# RA6M1 register map
Vendor: Renesas Electronics Corporation; Series: RA6; File version: 1.2
CPU: CM4 r0p1, little endian, MPU, FPU, VTOR, 4 interrupt priority bits
Registers are 8-bit, read-write, reset 0x0 unless marked. A register's access mark holds for its fields unless they carry their own. Offsets are from the block's base; [hi:lo] are bit positions; {n}, {i} and the like mark numbered series; 'fields as' and 'values as' point back to an identical list.

## PFS — Pmn Pin Function Control Register
Base 0x40040800
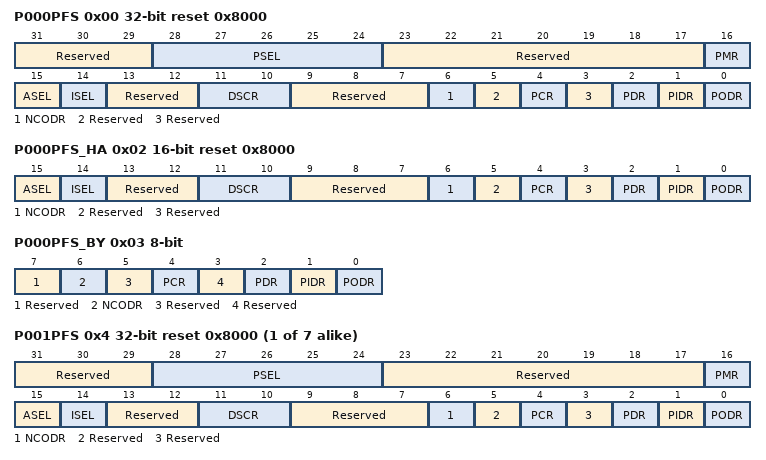
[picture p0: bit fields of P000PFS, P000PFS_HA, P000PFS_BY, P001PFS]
0x00 P000PFS 32-bit reset 0x8000 (reset mask 0xFFFFFFFD) — P000 Pin Function Control Register
  [31:29] Reserved — These bits are read as 000. The write value should be 000.
  [28:24] PSEL — Port Function Select These bits select the peripheral function. For individual pin functions, see the MPC table
  [23:17] Reserved — These bits are read as 0000000. The write value should be 0000000.
  [16] PMR — Port Mode Control
    0=Uses the pin as a general I/O pin; 1=Uses the pin as an I/O port for peripheral functions
  [15] ASEL — Analog Input enable
    0=Used other than as analog pin; 1=Used as analog pin
  [14] ISEL — IRQ input enable
    0=Not used as IRQn input pin; 1=Used as IRQn input pin
  [13:12] Reserved — These bits are read as 00. The write value should be 00.
  [11:10] DSCR — Drive Strength Control Register
    0=Normal drive output; 1=Middle drive output; 2=Setting prohibited; 3=High-drive output
  [9:7] Reserved — These bits are read as 000. The write value should be 000.
  [6] NCODR — N-Channel Open Drain Control
    0=CMOS output; 1=NMOS open-drain output
  [5] Reserved — This bit is read as 0. The write value should be 0.
  [4] PCR — Pull-up Control
    0=Disables an input pull-up; 1=Enables an input pull-up
  [3] Reserved — This bit is read as 0. The write value should be 0.
  [2] PDR — Port Direction
    0=Input (Functions as an input pin.); 1=Output (Functions as an output pin.)
  [1] PIDR ro — Port Input Data
    0=Low input; 1=High input
  [0] PODR — Port Output Data
    0=Low output; 1=High output
0x02 P000PFS_HA 16-bit reset 0x8000 (reset mask 0xFFFD) (alternate view of P000PFS) — P000 Pin Function Control Register
  [15] ASEL — Analog Input enable
    0=Used other than as analog pin; 1=Used as analog pin
  [14] ISEL — IRQ input enable
    0=Not used as IRQn input pin; 1=Used as IRQn input pin
  [13:12] Reserved — These bits are read as 00. The write value should be 00.
  [11:10] DSCR — Drive Strength Control Register
    values as P000PFS.DSCR
  [9:7] Reserved — These bits are read as 000. The write value should be 000.
  [6] NCODR — N-Channel Open Drain Control
    0=CMOS output; 1=NMOS open-drain output
  [5] Reserved — This bit is read as 0. The write value should be 0.
  [4] PCR — Pull-up Control
    0=Disables an input pull-up; 1=Enables an input pull-up
  [3] Reserved — This bit is read as 0. The write value should be 0.
  [2] PDR — Port Direction
    values as P000PFS.PDR
  [1] PIDR ro — Port Input Data
    0=Low input; 1=High input
  [0] PODR — Port Output Data
    0=Low output; 1=High output
0x03 P000PFS_BY (reset mask 0xFD) (alternate view of P000PFS) — P000 Pin Function Control Register
  [7] Reserved — This bit is read as 0. The write value should be 0.
  [6] NCODR — N-Channel Open Drain Control
    0=CMOS output; 1=NMOS open-drain output
  [5] Reserved — This bit is read as 0. The write value should be 0.
  [4] PCR — Pull-up Control
    0=Disables an input pull-up; 1=Enables an input pull-up
  [3] Reserved — This bit is read as 0. The write value should be 0.
  [2] PDR — Port Direction
    values as P000PFS.PDR
  [1] PIDR ro — Port Input Data
    0=Low input; 1=High input
  [0] PODR — Port Output Data
    0=Low output; 1=High output
{0x0+4i} P00{i}PFS (i=1..7) 32-bit reset 0x8000 (reset mask 0xFFFFFFFD) — P00{i} Pin Function Control Register
  fields as P000PFS
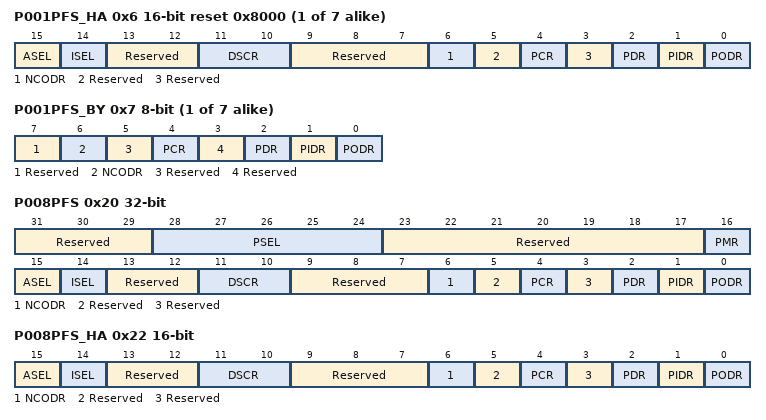
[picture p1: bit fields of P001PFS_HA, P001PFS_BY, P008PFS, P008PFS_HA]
{0x2+4i} P00{i}PFS_HA (i=1..7) 16-bit reset 0x8000 (reset mask 0xFFFD) (alternate view of P00{i}PFS) — P00{i} Pin Function Control Register
  fields as P000PFS_HA
{0x3+4i} P00{i}PFS_BY (i=1..7) (reset mask 0xFD) (alternate view of P00{i}PFS) — P00{i} Pin Function Control Register
  fields as P000PFS_BY
0x20 P008PFS 32-bit (reset mask 0xFFFFFFFD) — P008 Pin Function Control Register
  fields as P000PFS
0x22 P008PFS_HA 16-bit (reset mask 0xFFFD) (alternate view of P00*PFS) — P008 Pin Function Control Register
  fields as P000PFS_HA
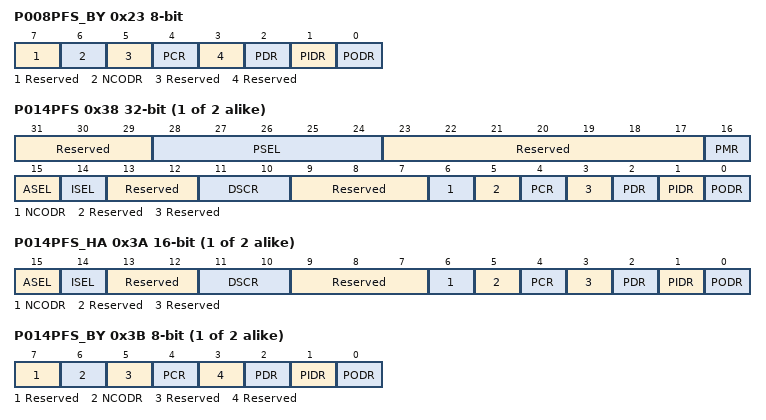
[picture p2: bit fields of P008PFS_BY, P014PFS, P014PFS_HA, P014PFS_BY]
0x23 P008PFS_BY (reset mask 0xFD) (alternate view of P00*PFS) — P008 Pin Function Control Register
  fields as P000PFS_BY
{0x0+4i} P0{i}PFS (i=14..15) 32-bit (reset mask 0xFFFFFFFD) — P0{i} Pin Function Control Register
  fields as P000PFS
{0x2+4i} P0{i}PFS_HA (i=14..15) 16-bit (reset mask 0xFFFD) — P0{i} Pin Function Control Register
  fields as P000PFS_HA
{0x3+4i} P0{i}PFS_BY (i=14..15) (reset mask 0xFD) — P0{i} Pin Function Control Register
  fields as P000PFS_BY
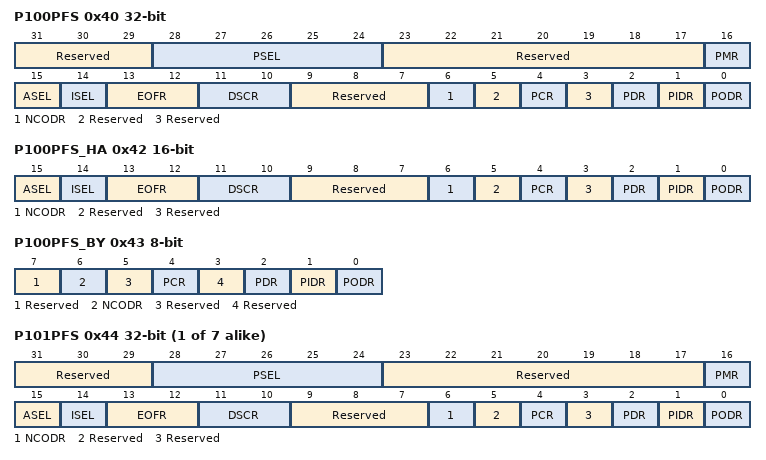
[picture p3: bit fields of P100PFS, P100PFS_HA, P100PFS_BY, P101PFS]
0x40 P100PFS 32-bit (reset mask 0xFFFFFFFD) — P100 Pin Function Control Register
  [31:29] Reserved — These bits are read as 000. The write value should be 000.
  [28:24] PSEL — Port Function Select These bits select the peripheral function. For individual pin functions, see the MPC table
  [23:17] Reserved — These bits are read as 0000000. The write value should be 0000000.
  [16] PMR — Port Mode Control
    values as P000PFS.PMR
  [15] ASEL — Analog Input enable
    0=Used other than as analog pin; 1=Used as analog pin
  [14] ISEL — IRQ input enable
    0=Not used as IRQn input pin; 1=Used as IRQn input pin
  [13:12] EOFR — Event on Falling/Event on Rising
    0=Don’t-care; 1=Detect rising edge; 2=Detect falling edge; 3=Detect both edges
  [11:10] DSCR — Drive Strength Control Register
    values as P000PFS.DSCR
  [9:7] Reserved — These bits are read as 000. The write value should be 000.
  [6] NCODR — N-Channel Open Drain Control
    0=CMOS output; 1=NMOS open-drain output
  [5] Reserved — This bit is read as 0. The write value should be 0.
  [4] PCR — Pull-up Control
    0=Disables an input pull-up; 1=Enables an input pull-up
  [3] Reserved — This bit is read as 0. The write value should be 0.
  [2] PDR — Port Direction
    values as P000PFS.PDR
  [1] PIDR ro — Port Input Data
    0=Low input; 1=High input
  [0] PODR — Port Output Data
    0=Low output; 1=High output
0x42 P100PFS_HA 16-bit (reset mask 0xFFFD) — P100 Pin Function Control Register
  [15] ASEL — Analog Input enable
    0=Used other than as analog pin; 1=Used as analog pin
  [14] ISEL — IRQ input enable
    0=Not used as IRQn input pin; 1=Used as IRQn input pin
  [13:12] EOFR — Event on Falling/Event on Rising
    values as P100PFS.EOFR
  [11:10] DSCR — Drive Strength Control Register
    values as P000PFS.DSCR
  [9:7] Reserved — These bits are read as 000. The write value should be 000.
  [6] NCODR — N-Channel Open Drain Control
    0=CMOS output; 1=NMOS open-drain output
  [5] Reserved — This bit is read as 0. The write value should be 0.
  [4] PCR — Pull-up Control
    0=Disables an input pull-up; 1=Enables an input pull-up
  [3] Reserved — This bit is read as 0. The write value should be 0.
  [2] PDR — Port Direction
    values as P000PFS.PDR
  [1] PIDR ro — Port Input Data
    0=Low input; 1=High input
  [0] PODR — Port Output Data
    0=Low output; 1=High output
0x43 P100PFS_BY (reset mask 0xFD) — P100 Pin Function Control Register
  fields as P000PFS_BY
{0x40+4i} P10{i}PFS (i=1..7) 32-bit (reset mask 0xFFFFFFFD) (alternate view of P10{i}PFS) — P10{i} Pin Function Control Register
  fields as P100PFS
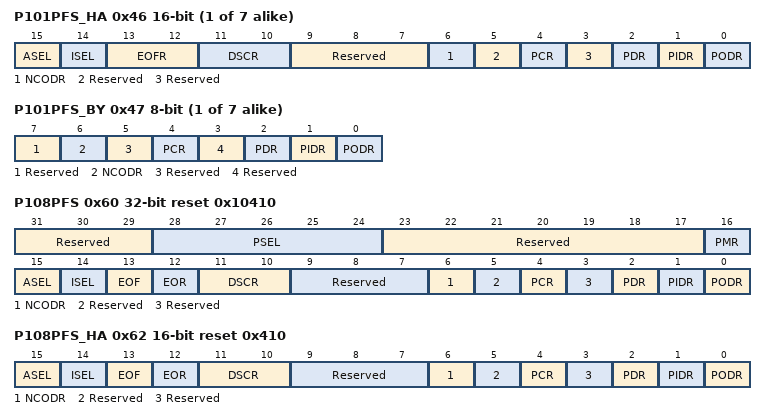
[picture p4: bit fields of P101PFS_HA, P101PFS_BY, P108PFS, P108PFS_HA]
{0x42+4i} P10{i}PFS_HA (i=1..7) 16-bit (reset mask 0xFFFD) (alternate view of P10{i}PFS) — P10{i} Pin Function Control Register
  fields as P100PFS_HA
{0x43+4i} P10{i}PFS_BY (i=1..7) (reset mask 0xFD) (alternate view of P10{i}PFS) — P10{i} Pin Function Control Register
  fields as P000PFS_BY
0x60 P108PFS 32-bit reset 0x10410 (reset mask 0xFFFFFFFD) — P108 Pin Function Control Register
  [31:29] Reserved — These bits are read as 000. The write value should be 000.
  [28:24] PSEL — Port Function Select These bits select the peripheral function. For individual pin functions, see the MPC table
  [23:17] Reserved — These bits are read as 0000000. The write value should be 0000000.
  [16] PMR — Port Mode Control
    values as P000PFS.PMR
  [15] ASEL — Analog Input enable
    0=Used other than as analog pin; 1=Used as analog pin
  [14] ISEL — IRQ input enable
    0=Not used as IRQn input pin; 1=Used as IRQn input pin
  [13] EOF — Event on Falling
    0=Do not care; 1=Detect falling edge
  [12] EOR — Event on Rising
    0=Do not care; 1=Detect rising edge
  [11:10] DSCR — Drive Strength Control Register
    values as P000PFS.DSCR
  [9:7] Reserved — These bits are read as 000. The write value should be 000.
  [6] NCODR — N-Channel Open Drain Control
    0=CMOS output; 1=NMOS open-drain output
  [5] Reserved — This bit is read as 0. The write value should be 0.
  [4] PCR — Pull-up Control
    0=Disables an input pull-up; 1=Enables an input pull-up
  [3] Reserved — This bit is read as 0. The write value should be 0.
  [2] PDR — Port Direction
    values as P000PFS.PDR
  [1] PIDR ro — Port Input Data
    0=Low input; 1=High input
  [0] PODR — Port Output Data
    0=Low output; 1=High output
0x62 P108PFS_HA 16-bit reset 0x410 (reset mask 0xFFFD) (alternate view of P108PFS) — P108 Pin Function Control Register
  [15] ASEL — Analog Input enable
    0=Used other than as analog pin; 1=Used as analog pin
  [14] ISEL — IRQ input enable
    0=Not used as IRQn input pin; 1=Used as IRQn input pin
  [13] EOF — Event on Falling
    0=Do not care; 1=Detect falling edge
  [12] EOR — Event on Rising
    0=Do not care; 1=Detect rising edge
  [11:10] DSCR — Drive Strength Control Register
    values as P000PFS.DSCR
  [9:7] Reserved — These bits are read as 000. The write value should be 000.
  [6] NCODR — N-Channel Open Drain Control
    0=CMOS output; 1=NMOS open-drain output
  [5] Reserved — This bit is read as 0. The write value should be 0.
  [4] PCR — Pull-up Control
    0=Disables an input pull-up; 1=Enables an input pull-up
  [3] Reserved — This bit is read as 0. The write value should be 0.
  [2] PDR — Port Direction
    values as P000PFS.PDR
  [1] PIDR ro — Port Input Data
    0=Low input; 1=High input
  [0] PODR — Port Output Data
    0=Low output; 1=High output
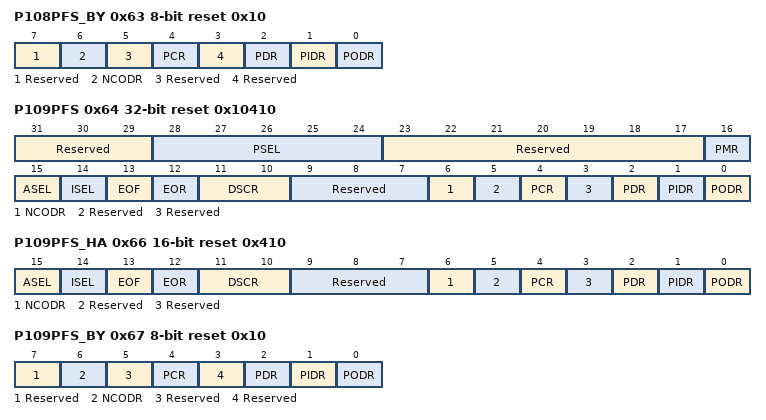
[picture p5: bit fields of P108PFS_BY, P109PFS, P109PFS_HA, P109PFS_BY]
0x63 P108PFS_BY reset 0x10 (reset mask 0xFD) (alternate view of P108PFS) — P108 Pin Function Control Register
  fields as P000PFS_BY
0x64 P109PFS 32-bit reset 0x10410 (reset mask 0xFFFFFFFD) — P109 Pin Function Control Register
  fields as P108PFS
0x66 P109PFS_HA 16-bit reset 0x410 (reset mask 0xFFFD) (alternate view of P109PFS) — P109 Pin Function Control Register
  fields as P108PFS_HA
0x67 P109PFS_BY reset 0x10 (reset mask 0xFD) (alternate view of P109PFS) — P109 Pin Function Control Register
  fields as P000PFS_BY
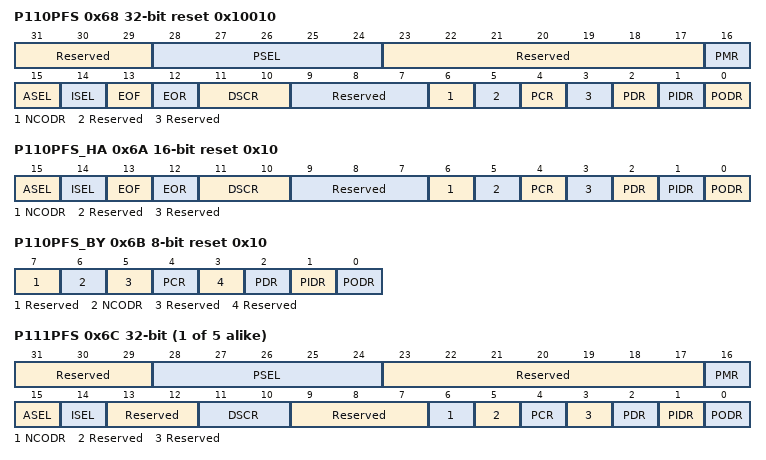
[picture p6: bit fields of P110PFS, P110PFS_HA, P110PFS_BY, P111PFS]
0x68 P110PFS 32-bit reset 0x10010 (reset mask 0xFFFFFFFD) — P110 Pin Function Control Register
  fields as P108PFS
0x6A P110PFS_HA 16-bit reset 0x10 (reset mask 0xFFFD) (alternate view of P110PFS) — P110 Pin Function Control Register
  fields as P108PFS_HA
0x6B P110PFS_BY reset 0x10 (reset mask 0xFD) (alternate view of P110PFS) — P110 Pin Function Control Register
  fields as P000PFS_BY
{0x40+4i} P1{i}PFS (i=11..15) 32-bit (reset mask 0xFFFFFFFD) — P1{i} Pin Function Control Register
  fields as P000PFS
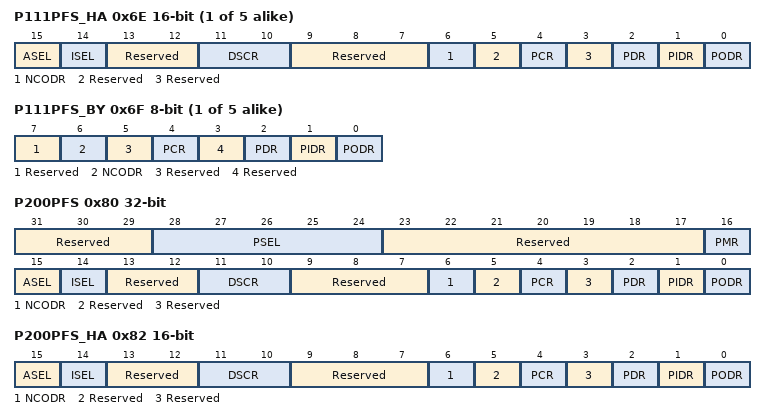
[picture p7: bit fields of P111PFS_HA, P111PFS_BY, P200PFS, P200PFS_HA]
{0x42+4i} P1{i}PFS_HA (i=11..15) 16-bit (reset mask 0xFFFD) (alternate view of P1{i}PFS) — P1{i} Pin Function Control Register
  fields as P000PFS_HA
{0x43+4i} P1{i}PFS_BY (i=11..15) (reset mask 0xFD) (alternate view of P1{i}PFS) — P1{i} Pin Function Control Register
  fields as P000PFS_BY
0x80 P200PFS 32-bit (reset mask 0xFFFFFFFD) — P200 Pin Function Control Register
  fields as P000PFS
0x82 P200PFS_HA 16-bit (reset mask 0xFFFD) (alternate view of P200PFS) — P200 Pin Function Control Register
  fields as P000PFS_HA
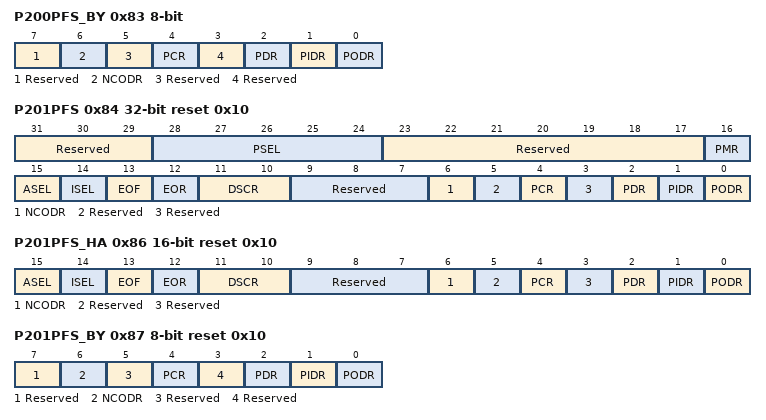
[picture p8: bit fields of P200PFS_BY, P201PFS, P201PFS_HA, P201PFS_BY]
0x83 P200PFS_BY (reset mask 0xFD) (alternate view of P200PFS) — P200 Pin Function Control Register
  fields as P000PFS_BY
0x84 P201PFS 32-bit reset 0x10 (reset mask 0xFFFFFFFD) — P201 Pin Function Control Register
  fields as P108PFS
0x86 P201PFS_HA 16-bit reset 0x10 (reset mask 0xFFFD) (alternate view of P201PFS) — P201 Pin Function Control Register
  fields as P108PFS_HA
0x87 P201PFS_BY reset 0x10 (reset mask 0xFD) (alternate view of P201PFS) — P201 Pin Function Control Register
  fields as P000PFS_BY
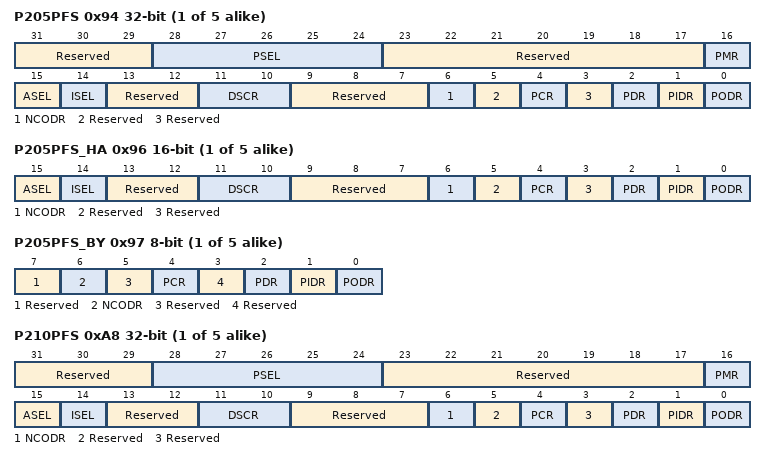
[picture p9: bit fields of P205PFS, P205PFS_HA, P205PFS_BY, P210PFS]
{0x80+4i} P20{i}PFS (i=5..9) 32-bit (reset mask 0xFFFFFFFD) — P20{i} Pin Function Control Register
  fields as P000PFS
{0x82+4i} P20{i}PFS_HA (i=5..9) 16-bit (reset mask 0xFFFD) (alternate view of P20{i}PFS) — P20{i} Pin Function Control Register
  fields as P000PFS_HA
{0x83+4i} P20{i}PFS_BY (i=5..9) (reset mask 0xFD) (alternate view of P20{i}PFS) — P20{i} Pin Function Control Register
  fields as P000PFS_BY
{0x80+4i} P2{i}PFS (i=10..14) 32-bit (reset mask 0xFFFFFFFD) — P2{i} Pin Function Control Register
  fields as P000PFS
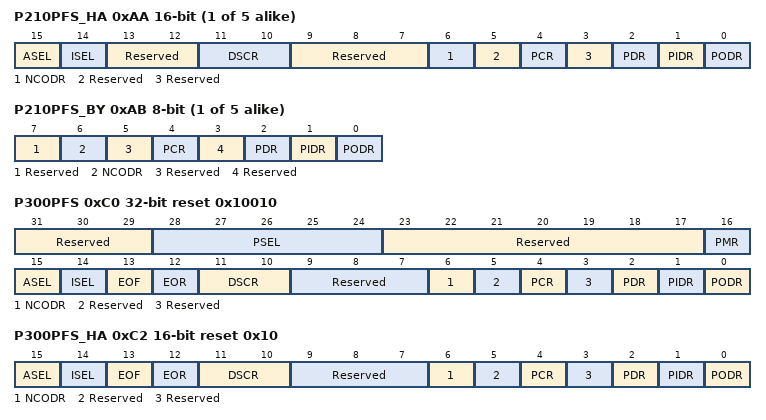
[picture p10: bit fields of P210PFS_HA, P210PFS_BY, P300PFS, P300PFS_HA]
{0x82+4i} P2{i}PFS_HA (i=10..14) 16-bit (reset mask 0xFFFD) (alternate view of P2{i}PFS) — P2{i} Pin Function Control Register
  fields as P000PFS_HA
{0x83+4i} P2{i}PFS_BY (i=10..14) (reset mask 0xFD) (alternate view of P2{i}PFS) — P2{i} Pin Function Control Register
  fields as P000PFS_BY
0xC0 P300PFS 32-bit reset 0x10010 (reset mask 0xFFFFFFFD) — P300 Pin Function Control Register
  fields as P108PFS
0xC2 P300PFS_HA 16-bit reset 0x10 (reset mask 0xFFFD) (alternate view of P300PFS) — P300 Pin Function Control Register
  fields as P108PFS_HA
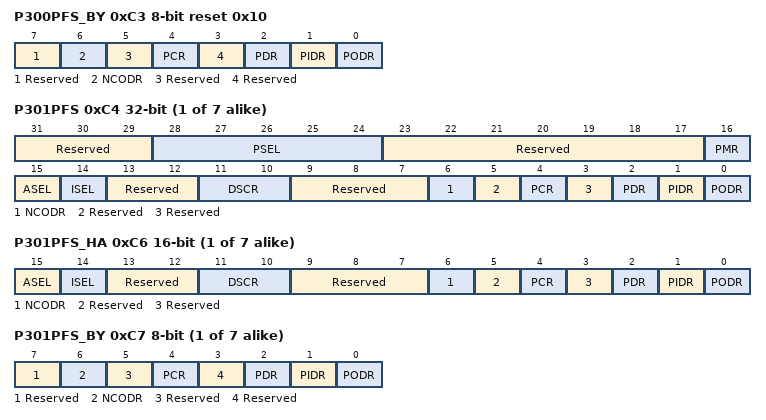
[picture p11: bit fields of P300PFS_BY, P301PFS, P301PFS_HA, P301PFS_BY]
0xC3 P300PFS_BY reset 0x10 (reset mask 0xFD) (alternate view of P300PFS) — P300 Pin Function Control Register
  fields as P000PFS_BY
{0xC0+4i} P30{i}PFS (i=1..7) 32-bit (reset mask 0xFFFFFFFD) — P30{i} Pin Function Control Register
  fields as P000PFS
{0xC2+4i} P30{i}PFS_HA (i=1..7) 16-bit (reset mask 0xFFFD) (alternate view of P30{i}PFS) — P30{i} Pin Function Control Register
  fields as P000PFS_HA
{0xC3+4i} P30{i}PFS_BY (i=1..7) (reset mask 0xFD) (alternate view of P30{i}PFS) — P30{i} Pin Function Control Register
  fields as P000PFS_BY
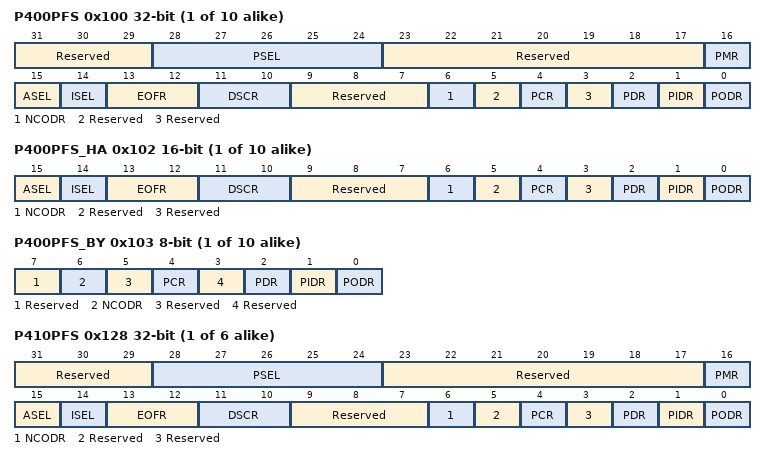
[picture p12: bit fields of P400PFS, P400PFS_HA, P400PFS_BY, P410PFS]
{0x100+4i} P40{i}PFS (i=0..9) 32-bit (reset mask 0xFFFFFFFD) — P40{i} Pin Function Control Register
  fields as P100PFS
{0x102+4i} P40{i}PFS_HA (i=0..9) 16-bit (reset mask 0xFFFD) (alternate view of P40{i}PFS) — P40{i} Pin Function Control Register
  fields as P100PFS_HA
{0x103+4i} P40{i}PFS_BY (i=0..9) (reset mask 0xFD) (alternate view of P40{i}PFS) — P40{i} Pin Function Control Register
  fields as P000PFS_BY
{0x100+4i} P4{i}PFS (i=10..15) 32-bit (reset mask 0xFFFFFFFD) — P4{i} Pin Function Control Register
  fields as P100PFS
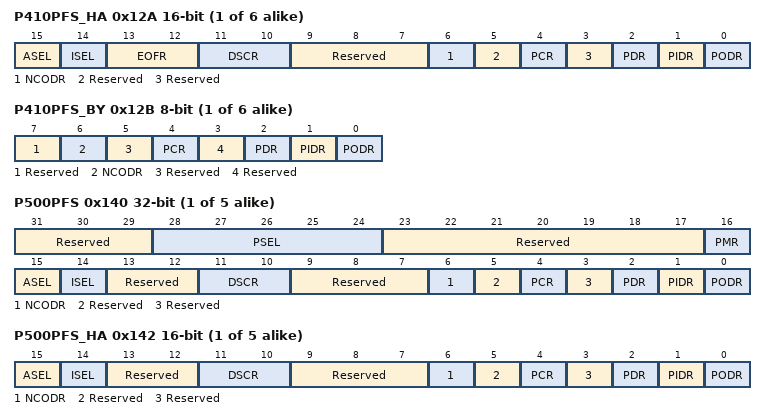
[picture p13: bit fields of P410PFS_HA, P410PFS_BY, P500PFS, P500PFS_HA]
{0x102+4i} P4{i}PFS_HA (i=10..15) 16-bit (reset mask 0xFFFD) (alternate view of P4{i}PFS) — P4{i} Pin Function Control Register
  fields as P100PFS_HA
{0x103+4i} P4{i}PFS_BY (i=10..15) (reset mask 0xFD) (alternate view of P4{i}PFS) — P4{i} Pin Function Control Register
  fields as P000PFS_BY
{0x140+4i} P50{i}PFS (i=0..4) 32-bit (reset mask 0xFFFFFFFD) — P50{i} Pin Function Control Register
  fields as P000PFS
{0x142+4i} P50{i}PFS_HA (i=0..4) 16-bit (reset mask 0xFFFD) (alternate view of P50{i}PFS) — P50{i} Pin Function Control Register
  fields as P000PFS_HA
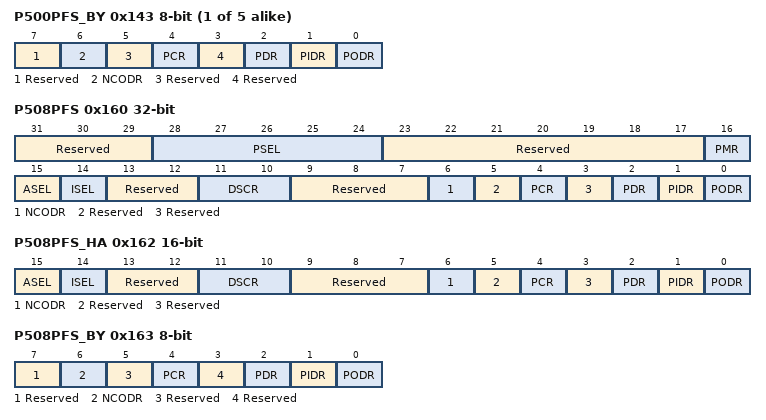
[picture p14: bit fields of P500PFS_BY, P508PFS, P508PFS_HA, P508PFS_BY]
{0x143+4i} P50{i}PFS_BY (i=0..4) (reset mask 0xFD) (alternate view of P50{i}PFS) — P50{i} Pin Function Control Register
  fields as P000PFS_BY
0x160 P508PFS 32-bit (reset mask 0xFFFFFFFD) — P508 Pin Function Control Register
  fields as P000PFS
0x162 P508PFS_HA 16-bit (reset mask 0xFFFD) (alternate view of P508PFS) — P508 Pin Function Control Register
  fields as P000PFS_HA
0x163 P508PFS_BY (reset mask 0xFD) (alternate view of P508PFS) — P508 Pin Function Control Register
  fields as P000PFS_BY
{0x180+4i} P60{i}PFS (i=0..2) 32-bit (reset mask 0xFFFFFFFD) — P60{i} Pin Function Control Register
  fields as P000PFS
{0x182+4i} P60{i}PFS_HA (i=0..2) 16-bit (reset mask 0xFFFD) (alternate view of P60{i}PFS) — P60{i} Pin Function Control Register
  fields as P000PFS_HA
{0x183+4i} P60{i}PFS_BY (i=0..2) (reset mask 0xFD) (alternate view of P60{i}PFS) — P60{i} Pin Function Control Register
  fields as P000PFS_BY
{0x180+4i} P60{i}PFS (i=8..9) 32-bit (reset mask 0xFFFFFFFD) — P60{i} Pin Function Control Register
  fields as P000PFS
{0x182+4i} P60{i}PFS_HA (i=8..9) 16-bit (reset mask 0xFFFD) (alternate view of P60{i}PFS) — P60{i} Pin Function Control Register
  fields as P000PFS_HA
{0x183+4i} P60{i}PFS_BY (i=8..9) (reset mask 0xFD) (alternate view of P60{i}PFS) — P60{i} Pin Function Control Register
  fields as P000PFS_BY
0x1A8 P610PFS 32-bit (reset mask 0xFFFFFFFD) — P610 Pin Function Control Register
  fields as P000PFS
0x1AA P610PFS_HA 16-bit (reset mask 0xFFFD) (alternate view of P6*PFS) — P610 Pin Function Control Register
  fields as P000PFS_HA
0x1AB P610PFS_BY (reset mask 0xFD) (alternate view of P6*PFS) — P610 Pin Function Control Register
  fields as P000PFS_BY
0x1E0 P708PFS 32-bit (reset mask 0xFFFFFFFD) — P708 Pin Function Control Register
  fields as P000PFS
0x1E2 P708PFS_HA 16-bit (reset mask 0xFFFD) (alternate view of P70*PFS) — P708 Pin Function Control Register
  fields as P000PFS_HA
0x1E3 P708PFS_BY (reset mask 0xFD) (alternate view of P70*PFS) — P708 Pin Function Control Register
  fields as P000PFS_BY
